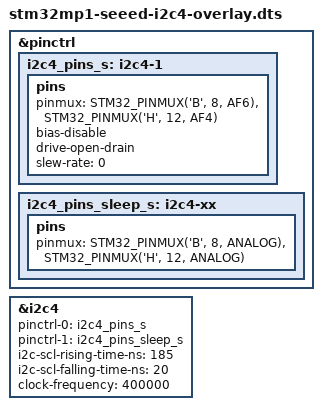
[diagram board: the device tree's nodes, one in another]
/*
 * Copyright (C) 2018 Robert Nelson <robertcnelson@gmail.com>
 *
 * This program is free software; you can redistribute it and/or modify
 * it under the terms of the GNU General Public License version 2 as
 * published by the Free Software Foundation.
 *
 * https://www.adafruit.com/product/3386
 */

/dts-v1/;
/plugin/;

#include <dt-bindings/gpio/gpio.h>
#include <dt-bindings/pinctrl/stm32-pinfunc.h>

/ {
        /*
        * Helper to show loaded overlays under: /proc/device-tree/chosen/overlays/
        */

        fragment@0 {
                target = <&pinctrl>;
                __overlay__ {
                        i2c4_pins_s: i2c4-1 {
                                pins {
                                        pinmux = <STM32_PINMUX('B', 8, AF6)>, /* I2C4_SCL */
                                                        <STM32_PINMUX('H', 12, AF4)>; /* I2C4_SDA */
                                        bias-disable;                 /*pull disable*/
                                        drive-open-drain;             /*open drain enable*/
                                        slew-rate = <0>;
                                };
                        };
                        i2c4_pins_sleep_s: i2c4-xx {
                                pins {
                                        pinmux = <STM32_PINMUX('B', 8, ANALOG)>, /* I2C4_SCL */
                                                        <STM32_PINMUX('H', 12, ANALOG)>; /* I2C4_SCL */
                                };
                        };
                };
        };

        fragment@1 {
                target = <&i2c4>;
                __overlay__ {
                        pinctrl-names = "default", "sleep";
                        pinctrl-0 = <&i2c4_pins_s>;
                        pinctrl-1 = <&i2c4_pins_sleep_s>;
                        i2c-scl-rising-time-ns = <185>;
                        i2c-scl-falling-time-ns = <20>;
                        clock-frequency = <400000>;
                        status = "okay";
                        /delete-property/dmas;
                        /delete-property/dma-names;
                };
	};
};
